# Management Filters Register Definitions: IP-XACT component
VLNV meklort:<PROJECT>:Management Filters Register Definitions:1.0

## Address spaces and blocks
FILTERS0.FILTERS0: base 0xA0048000, range , width 

## Registers
Registers are 32-bit, read-write, no defined reset value unless marked. A register's access mark holds for its fields unless they carry their own. Offsets are from the block's base; lines under a group give offsets from that group; [hi:lo] are bit positions; {n}, {i} and the like mark numbered series; 'fields as' and 'values as' point back to an identical list; <NAME> marks a mode.

## FILTERS0.FILTERS0 — Management Filter Registers
Base 0xA0048000
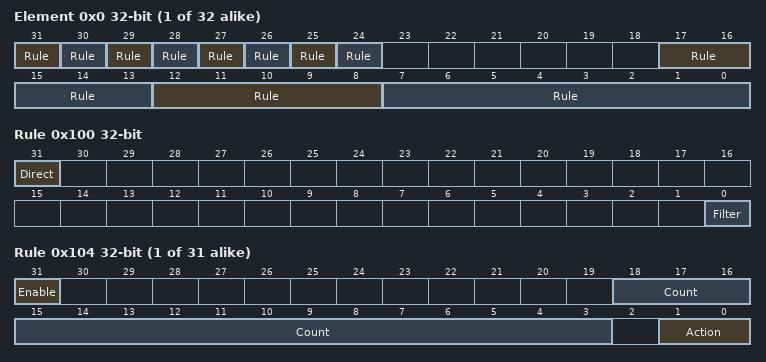
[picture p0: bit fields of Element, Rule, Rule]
{0x0+4i} Element Config[{i}] (i=0..31) — Element Configuration Register.
  [31] Rule Enable
  [30] Rule And
  [29] Rule P1
  [28] Rule P2
  [27] Rule P3
  [26] Rule Mask
  [25] Rule Discard
  [24] Rule Map
  [17:16] Rule Op
    0=EQ; 1=NE; 2=GT; 3=LT
  [15:13] Rule Header
    0=SOF; 1=IP; 2=TCP; 3=UDP; 4=DATA; 5=ICMPv4; 6=ICMPv6; 7=VLAN
  [12:8] Rule Class
  [7:0] Rule Offset
{0x80+4i} Element Pattern[{i}] (i=0..31) access not given — If RULE_MASK is set, low 16 bits are a bitmask and high 16 bits are the value masked by it. If it is not set, the entire field is a 32-bit match value.
0x100 Rule Configuration
  [31] Direct IP Fragment to APE, [0] Filter Set Disable
{0x104+4i} Rule Set[{i}] (i=0..30)
  [31] Enable
  [18:3] Count
  [1:0] Action
    0=To APE Only; 1=To APE And Host; 2=Discard
{0x184+4i} Rule Mask[{i}] (i=0..30) access not given
